# ATxmega128D3 device description
Architecture: AVR8_XMEGA; Family: AVR XMEGA
Registers are 8-bit, access not given, no defined reset value unless marked. A register's access mark holds for its fields unless they carry their own. Offsets are from the block's base; [hi:lo] are bit positions; lines under a group give offsets from that group; {n}, {i} and the like mark numbered series; 'fields as' and 'values as' point back to an identical list.

## NVM_PROD_SIGNATURES — Production Signatures
Instances: PROD_SIGNATURES 0x00 in prod_signatures
0x00 RCOSC2M — RCOSC 2MHz Calibration Value B
0x01 RCOSC2MA — RCOSC 2MHz Calibration Value A
0x02 RCOSC32K — RCOSC 32kHz Calibration Value
0x03 RCOSC32M — RCOSC 32MHz Calibration Value B
0x04 RCOSC32MA — RCOSC 32MHz Calibration Value A
{0x8+i} LOTNUM{i} (i=0..5) — Lot Number Byte {i}, ASCII
0x10 WAFNUM — Wafer Number
0x12 COORDX0 — Wafer Coordinate X Byte 0
0x13 COORDX1 — Wafer Coordinate X Byte 1
0x14 COORDY0 — Wafer Coordinate Y Byte 0
0x15 COORDY1 — Wafer Coordinate Y Byte 1
0x20 ADCACAL0 — ADCA Calibration Byte 0
0x21 ADCACAL1 — ADCA Calibration Byte 1
0x24 ADCBCAL0 — ADCB Calibration Byte 0
0x25 ADCBCAL1 — ADCB Calibration Byte 1
0x2E TEMPSENSE0 — Temperature Sensor Calibration Byte 0
0x2F TEMPSENSE1 — Temperature Sensor Calibration Byte 0

## AC — Analog Comparator
Instances: ACA 0x0380
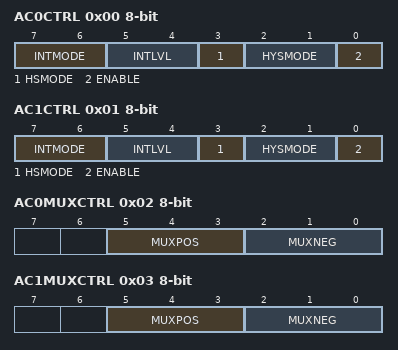
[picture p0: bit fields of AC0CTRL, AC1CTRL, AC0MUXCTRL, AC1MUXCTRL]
0x00 AC0CTRL — Analog Comparator 0 Control
  [7:6] INTMODE — Interrupt Mode
    0=BOTHEDGES (Interrupt on both edges); 2=FALLING (Interrupt on falling edge); 3=RISING (Interrupt on rising edge)
  [5:4] INTLVL — Interrupt Level
    0=OFF (Interrupt disabled); 1=LO (Low level); 2=MED (Medium level); 3=HI (High level)
  [3] HSMODE — High-speed Mode
  [2:1] HYSMODE — Hysteresis Mode
    0=NO (No hysteresis); 1=SMALL (Small hysteresis); 2=LARGE (Large hysteresis)
  [0] ENABLE
0x01 AC1CTRL — Analog Comparator 1 Control
  fields as AC0CTRL
0x02 AC0MUXCTRL — Analog Comparator 0 MUX Control
  [5:3] MUXPOS — MUX Positive Input
    {v}=PIN{v} (v=0..6); 7=DAC (DAC output)
  [2:0] MUXNEG — MUX Negative Input
    0=PIN0; 1=PIN1; 2=PIN3; 3=PIN5; 4=PIN7; 5=DAC (DAC output); 6=BANDGAP (Bandgap Reference); 7=SCALER (Internal voltage scaler)
0x03 AC1MUXCTRL — Analog Comparator 1 MUX Control
  fields as AC0MUXCTRL
0x04 CTRLA — Control Register A
  [0] AC0OUT — Analog Comparator 0 Output Enable
0x05 CTRLB — Control Register B
  [5:0] SCALEFAC — VCC Voltage Scaler Factor
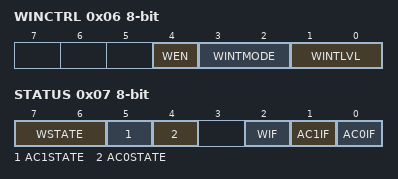
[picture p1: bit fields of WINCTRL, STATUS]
0x06 WINCTRL — Window Mode Control
  [4] WEN — Window Mode Enable
  [3:2] WINTMODE — Window Interrupt Mode
    0=ABOVE (Interrupt on above window); 1=INSIDE (Interrupt on inside window); 2=BELOW (Interrupt on below window); 3=OUTSIDE (Interrupt on outside window)
  [1:0] WINTLVL — Window Interrupt Level
    0=OFF (Interrupt disabled); 1=LO (Low priority); 2=MED (Medium priority); 3=HI (High priority)
0x07 STATUS
  [7:6] WSTATE — Window Mode State
    0=ABOVE (Signal above window); 1=INSIDE (Signal inside window); 2=BELOW (Signal below window)
  [5] AC1STATE — Analog Comparator 1 State
  [4] AC0STATE — Analog Comparator 0 State
  [2] WIF — Window Mode Interrupt Flag
  [1] AC1IF — Analog Comparator 1 Interrupt Flag
  [0] AC0IF — Analog Comparator 0 Interrupt Flag

## RTC — Real-Time Counter
Instances: RTC 0x0400
0x00 CTRL — Control Register
  [2:0] PRESCALER — Prescaling Factor
    0=OFF (RTC Off); 1=DIV1 (RTC Clock); 2=DIV2 (RTC Clock / 2); 3=DIV8 (RTC Clock / 8); 4=DIV16 (RTC Clock / 16); 5=DIV64 (RTC Clock / 64); 6=DIV256 (RTC Clock / 256); 7=DIV1024 (RTC Clock / 1024)
0x01 STATUS
  [0] SYNCBUSY — Synchronization Busy Flag
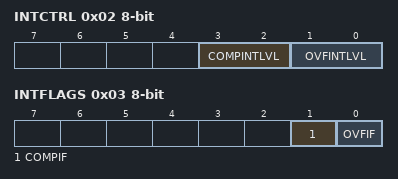
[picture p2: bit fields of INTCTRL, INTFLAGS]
0x02 INTCTRL — Interrupt Control Register
  [3:2] COMPINTLVL — Compare Match Interrupt Level
    0=OFF (Interrupt Disabled); 1=LO (Low Level); 2=MED (Medium Level); 3=HI (High Level)
  [1:0] OVFINTLVL — Overflow Interrupt Level
    values as COMPINTLVL
0x03 INTFLAGS — Interrupt Flags
  [1] COMPIF — Compare Match Interrupt Flag
  [0] OVFIF — Overflow Interrupt Flag
0x04 TEMP — Temporary register
0x08 CNT 16-bit — Count Register
0x0A PER 16-bit — Period Register
0x0C COMP 16-bit — Compare Register

## TWI — Two-Wire Interface
Instances: TWIC 0x480, TWIE 0x4A0
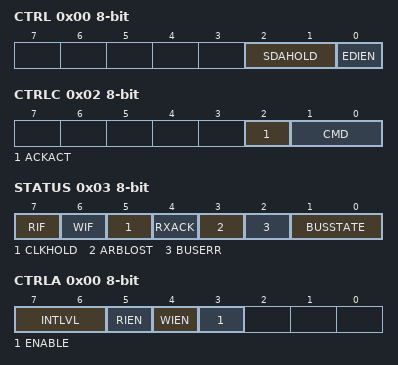
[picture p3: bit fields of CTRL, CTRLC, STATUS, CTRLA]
0x00 CTRL — TWI Common Control Register
  [2:1] SDAHOLD — SDA Hold Time Enable
    0=OFF (SDA hold time off); 1=50NS (Typical 50ns hold time); 2=300NS (Typical 300ns hold time); 3=400NS (Typical 400ns hold time)
  [0] EDIEN — External Driver Interface Enable
0x01 MASTER group — TWI master module
  0x00 CTRLA — Control Register A
    [7:6] INTLVL — Interrupt Level
      0=OFF (Interrupt Disabled); 1=LO (Low Level); 2=MED (Medium Level); 3=HI (High Level)
    [5] RIEN — Read Interrupt Enable
    [4] WIEN — Write Interrupt Enable
    [3] ENABLE — Enable TWI Master
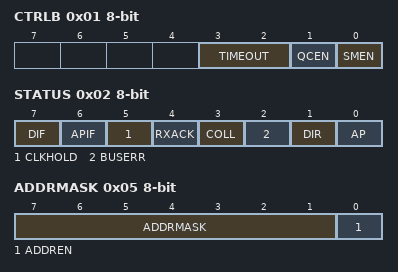
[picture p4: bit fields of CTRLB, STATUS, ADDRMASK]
  0x01 CTRLB — Control Register B
    [3:2] TIMEOUT — Inactive Bus timeout
      0=DISABLED (Bus Timeout Disabled); 1=50US (50 Microseconds); 2=100US (100 Microseconds); 3=200US (200 Microseconds)
    [1] QCEN — Quick Command Enable
    [0] SMEN — Smart Mode Enable
  0x02 CTRLC — Control Register C
    [2] ACKACT — Acknowledge Action
    [1:0] CMD — Command
      0=NOACT (No Action); 1=REPSTART (Issue Repeated Start Condition); 2=RECVTRANS (Receive or Transmit Data); 3=STOP (Issue Stop Condition)
  0x03 STATUS
    [7] RIF — Read Interrupt Flag
    [6] WIF — Write Interrupt Flag
    [5] CLKHOLD — Clock Hold
    [4] RXACK — Received Acknowledge
    [3] ARBLOST — Arbitration Lost
    [2] BUSERR — Bus Error
    [1:0] BUSSTATE
      0=UNKNOWN (Unknown Bus State); 1=IDLE (Bus is Idle); 2=OWNER (This Module Controls The Bus); 3=BUSY (The Bus is Busy)
  0x04 BAUD — Baurd Rate Control Register
  0x05 ADDR — Address Register
  0x06 DATA
0x08 SLAVE group — TWI slave module
  0x00 CTRLA — Control Register A
    [7:6] INTLVL — Interrupt Level
      values as MASTER.CTRLA.INTLVL
    [5] DIEN — Data Interrupt Enable
    [4] APIEN — Address/Stop Interrupt Enable
    [3] ENABLE — Enable TWI Slave
    [2] PIEN — Stop Interrupt Enable
    [1] PMEN — Promiscuous Mode Enable
    [0] SMEN — Smart Mode Enable
  0x01 CTRLB — Control Register B
    [2] ACKACT — Acknowledge Action
    [1:0] CMD — Command
      0=NOACT (No Action); 2=COMPTRANS (Used To Complete a Transaction); 3=RESPONSE (Used in Response to Address/Data Interrupt)
  0x02 STATUS
    [7] DIF — Data Interrupt Flag
    [6] APIF — Address/Stop Interrupt Flag
    [5] CLKHOLD — Clock Hold
    [4] RXACK — Received Acknowledge
    [3] COLL — Collision
    [2] BUSERR — Bus Error
    [1] DIR — Read/Write Direction
    [0] AP — Slave Address or Stop
  0x03 ADDR — Address Register
  0x04 DATA
  0x05 ADDRMASK — Address Mask Register
    [7:1] ADDRMASK — Address Mask
    [0] ADDREN — Address Enable
